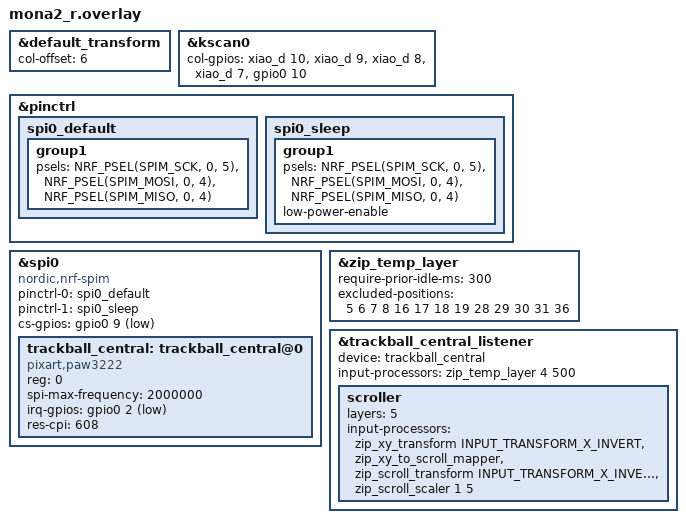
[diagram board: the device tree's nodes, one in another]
#include "mona2.dtsi"
#include <input/processors.dtsi>
#include <zephyr/dt-bindings/input/input-event-codes.h>


&default_transform {
    col-offset = <6>;
};

&kscan0 {
        col-gpios
            = <&xiao_d 10 GPIO_ACTIVE_HIGH>
            , <&xiao_d 9 GPIO_ACTIVE_HIGH> 
            , <&xiao_d 8 GPIO_ACTIVE_HIGH> 
            , <&xiao_d 7 GPIO_ACTIVE_HIGH> 
            , <&gpio0 10 GPIO_ACTIVE_HIGH>
            ;
};


&pinctrl {
    spi0_default: spi0_default {    //通常時(SPI通信中)のピン構成
        group1 {
            psels = <NRF_PSEL(SPIM_SCK, 0, 5)>, //P0.05を指定(SCLK)
                <NRF_PSEL(SPIM_MOSI, 0, 4)>,    //P0.04を指定(SDIOだからMOSI,MISO両方の役割を担う)
                <NRF_PSEL(SPIM_MISO, 0, 4)>;
        };
    };

    spi0_sleep: spi0_sleep {    //スリープ時のピン構成(省電力)
        group1 {
            psels = <NRF_PSEL(SPIM_SCK, 0, 5)>,
                <NRF_PSEL(SPIM_MOSI, 0, 4)>,
                <NRF_PSEL(SPIM_MISO, 0, 4)>;
            low-power-enable;
        };
    };
};


&spi0 {
    status = "okay";
    compatible = "nordic,nrf-spim"; //マイコンがnRFシリーズ
    pinctrl-0 = <&spi0_default>;
    pinctrl-1 = <&spi0_sleep>;
    pinctrl-names = "default", "sleep";
    cs-gpios = <&gpio0 9 GPIO_ACTIVE_LOW>;  //P0.09を指定(CS)

    trackball_central: trackball_central@0 {
        status = "okay";
        compatible = "pixart,paw3222";  //トラボセンサ用のドライバとバインド
        reg = <0>;
        spi-max-frequency = <2000000>;
        irq-gpios = <&gpio0 2 (GPIO_ACTIVE_LOW | GPIO_PULL_UP)>; //P0.02を指定(MOTION)

        // PAW3222 の解像度は 38 CPI 刻みで、有効範囲は 608 (16*38) 〜 4826 (127*38)。
        // 範囲外だと paw32xx_set_resolution が -EINVAL で設定をスキップする。
        // 608 は純正 PMW3610 版の cpi=600 に最も近い有効値。
        res-cpi = <608>;
    };
};


// Overrides for the input listener node
// === オートマウスレイヤー(BALL=4)の誤爆対策 ===
// zip_temp_layer 自体は移動量しきい値を持たないため、時間と打鍵で制御する。
&zip_temp_layer {
    // 直前の打鍵から 300ms 以内はボールを動かしても BALL 層へ入らない。
    // 150ms では 60 WPM の打鍵間隔 (約 200ms) を覆えず誤爆する。300ms は 40 WPM 相当。
    // 抑制されるのはレイヤー切替だけで、ポインタ移動は打鍵直後でも通る。
    require-prior-idle-ms = <300>;

    // ここに挙げた位置「以外」のキーを押すと BALL 層を即座に解除する。
    // = BALL 層で実際に使うキーだけを列挙 (位置番号は 0..41)。
    //    5  6  7  8      LC(W) 中クリック MB4 MB5
    //   16 17 18 19      ← 左クリック 右クリック →
    //   28 29 30 31      MO(SCROLL) スクロール下 スクロール上 LCTRL
    //   36               左親指 td_lctl (hold=LCTRL)
    //   ※ 上記以外は BALL 層で &none か &trans。押した時点で BALL 層を抜ける。
    excluded-positions = <5 6 7 8 16 17 18 19 28 29 30 31 36>;
};

&trackball_central_listener {
    status = "okay";
    device = <&trackball_central>;

    // ボール移動で BALL(4) 層へ / 停止後 500ms で復帰
    input-processors = <&zip_temp_layer 4 500>;

    scroller {
        layers = <5>;                                       //SCROLL 層
        input-processors = 
            // <&zip_xy_transform INPUT_TRANSFORM_XY_SWAP>,        //X軸とY軸の入れ替え
            <&zip_xy_transform INPUT_TRANSFORM_X_INVERT>,       //X軸反転
            <&zip_xy_to_scroll_mapper>,                         //スクロールモードに変更
            <&zip_scroll_transform INPUT_TRANSFORM_X_INVERT>,   //スクロールのX軸反転
            <&zip_scroll_scaler 1 5>;                           //スクロール量を1/4倍
    };

};
